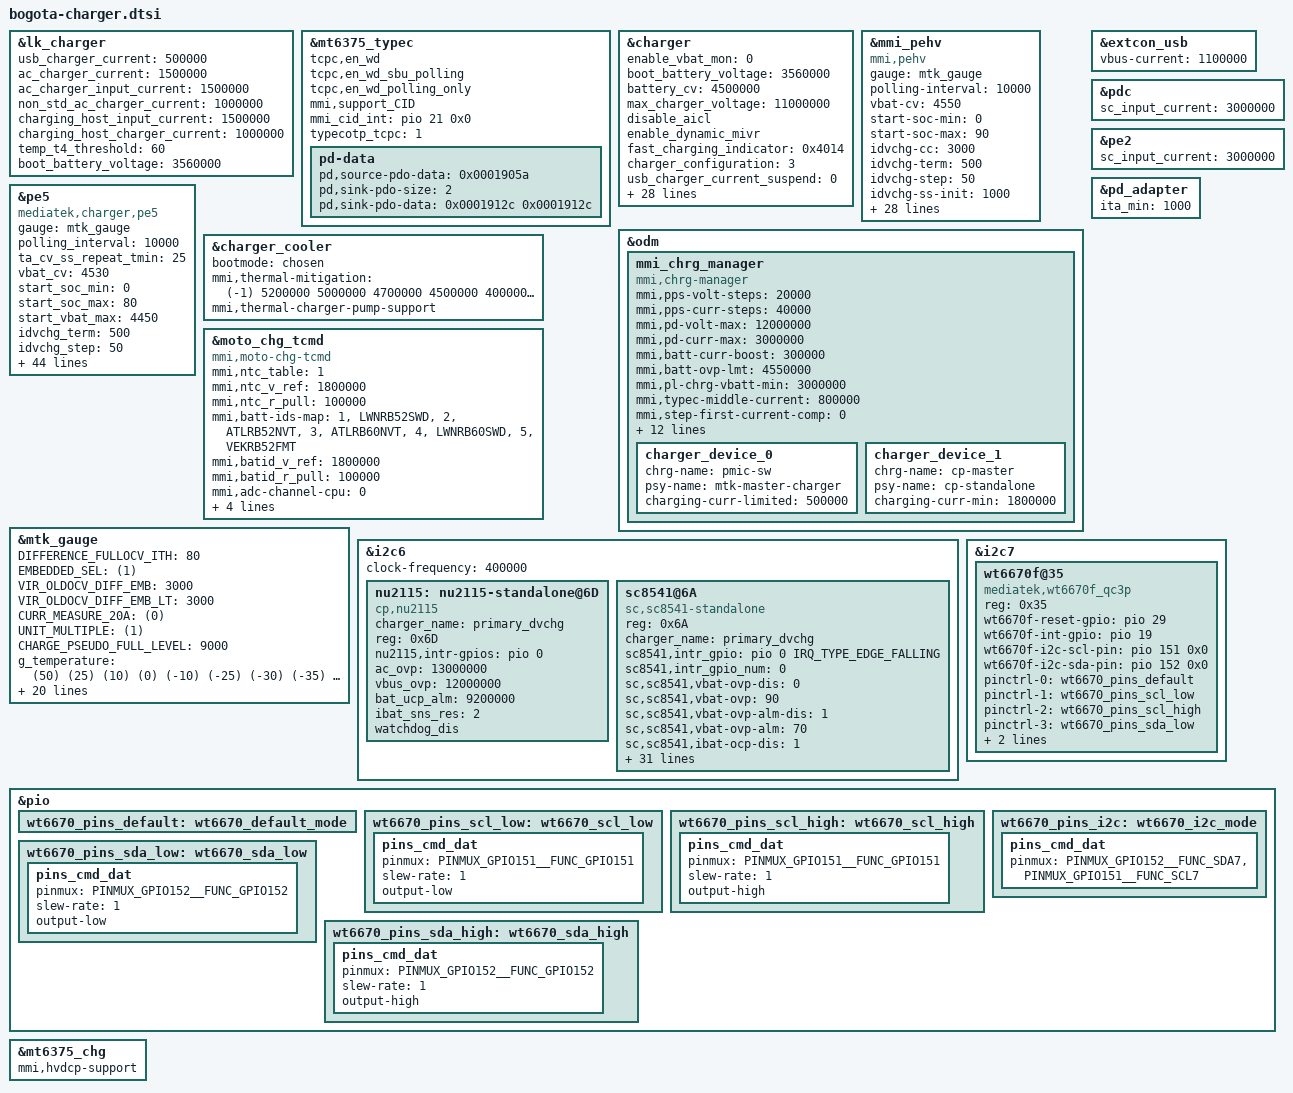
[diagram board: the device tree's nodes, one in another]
/*
 * Copyright (c) 2021 MediaTek Inc.
 *
 * This program is free software; you can redistribute it and/or modify
 * it under the terms of the GNU General Public License version 2 as
 * published by the Free Software Foundation.
 *
 * This program is distributed in the hope that it will be useful,
 * but WITHOUT ANY WARRANTY; without even the implied warranty of
 * MERCHANTABILITY or FITNESS FOR A PARTICULAR PURPOSE.  See the
 * GNU General Public License for more details.
 */

#include <dt-bindings/iio/adc/mediatek,mt6375_adc.h>

&lk_charger {
	/* charging current */
	usb_charger_current = <500000>;
	ac_charger_current = <1500000>;
	ac_charger_input_current = <1500000>;
	non_std_ac_charger_current = <1000000>;
	charging_host_input_current = <1500000>;
	charging_host_charger_current = <1000000>;

	temp_t4_threshold = <60>;

	boot_battery_voltage = <3560000>;
};

&mt6375_typec {
       tcpc,en_wd;
       tcpc,en_wd_sbu_polling;
       tcpc,en_wd_polling_only;
       mmi,support_CID;
       mmi_cid_int = <&pio 21 0x0>;
};

&charger {
        /* sw jeita */
        enable_vbat_mon = <0>;

	/* common */
        boot_battery_voltage = <3560000>;
	battery_cv = <4500000>;
	max_charger_voltage = <11000000>;
//	min_charger_voltage = <4600000>;

        disable_aicl;
        enable_dynamic_mivr;

	/*pehv && pe5 && pdc*/
	fast_charging_indicator = <0x4014>;
	/*swchg + 1CP*/
	charger_configuration= <3>;

	/* charging current */
	usb_charger_current_suspend = <0>;
	usb_charger_current_unconfigured = <70000>;
	usb_charger_current_configured = <500000>;
	usb_charger_current = <500000>;
	ac_charger_current = <3000000>;
	ac_charger_input_current = <2000000>;
	non_std_ac_charger_current = <1000000>;
	charging_host_charger_current = <1500000>;
	apple_1_0a_charger_current = <650000>;
	apple_2_1a_charger_current = <800000>;
	ta_ac_charger_current = <2000000>;
	typec_limit_aicr = <3000000>;
//	typecotp_charger = <1>;

	/*mmi config*/
	mmi,iterm-ma = <255>;
	mmi,mmi-temp-zones = <0 4200 1000 0>,
			<10 4250 2500 1500>,
                        <10 4500 1500 1500>,
			<15 4500 2500 2500>,
			<45 4300 6000 5200>,
			<45 4400 5400 4000>,
			<45 4530 4200 4000>,
			<60 4200 2500 0>;
	mmi,mmi-ffc-zones = <0 4200 255>,
			<10 4500 255>,
			<15 4500 255>,
			<25 4530 692>,
			<35 4530 780>,
			<45 4530 1142>,
			<60 4200 195>;

	mmi,mmi-normal-zones = <0 4200 255>,
			<10 4500 255>,
			<15 4500 255>,
			<25 4500 255>,
			<35 4500 255>,
			<45 4500 510>,
			<60 4200 195>;
	mmi,enable-charging-limit;
	mmi,upper-limit-capacity = <65>;
	mmi,lower-limit-capacity = <60>;
	mmi,min-cp-therm-current-ua = <900000>;
	enable-pdtest-mode = <1>;
};

&mmi_pehv {
	compatible = "mmi,pehv";
	gauge = <&mtk_gauge>;
	polling-interval = <10000>;
	vbat-cv = <4550>;
	start-soc-min = <0>;
	start-soc-max = <90>;
	idvchg-cc = <3000>;
	idvchg-term = <500>;
	idvchg-step = <50>;
	idvchg-ss-init = <1000>;
	idvchg-ss-step = <250>;
	idvchg-ss-step1 = <100>;
	idvchg-ss-step2 = <50>;
	idvchg-ss-step1-vbat = <4000>;
	idvchg-ss-step2-vbat = <4200>;
	ta-blanking = <400>;
	swchg-aicr = <0>;
	swchg-ichg = <1200>;
	swchg-aicr-ss-init = <400>;
	swchg-aicr-ss-step = <200>;
	swchg-off-vbat = <4250>;
	force-ta-cv-vbat = <4250>;
	chg-time-max = <10800>;
	ifod-threshold = <200>;
	rsw-min = <20>;
	ircmp-rbat = <40>;
	ircmp-vclamp = <0>;
	vta-cap-min = <6800>;
	vta-cap-max = <11000>;
	vta-step = <20>;
	ita-cap-min = <1000>;
	vbat-threshold = <4150>;
	min-charger-voltage = <4600000>;
	mmi_therm_cur_thres = <500>;
	mmi_therm_vol_thres = <80>;
	mmi_therm_step = <3>;
	mmi_max_ibat = <6000>;
	ibus-ocp-ratio = <120>;
};

&odm {
	mmi_chrg_manager {
		compatible = "mmi,chrg-manager";
		mmi,pps-volt-steps = <20000>;
		mmi,pps-curr-steps = <40000>;
		mmi,pd-volt-max = <12000000>;
		mmi,pd-curr-max = <3000000>;
		mmi,batt-curr-boost = <300000>;
		mmi,batt-ovp-lmt = <4550000>;
		mmi,pl-chrg-vbatt-min = <3000000>;
		mmi,typec-middle-current = <800000>;
		mmi,step-first-current-comp = <0>;
		mmi,dont-rerun-aicl;
		mmi,chrg-temp-zones-num = <5>;
		mmi,mmi-chrg-temp-zones =
				<0 4200 1000  0 0 0 0>,
				<10 4250 3000 4500 1000 0 0>,
				<15 4500 3000 0 0 0 0>,
				<45 4300 6000 4400 5200 4530 4000>,
				<60 4200 4000 0 0 0 0>;

		mmi,mmi-ffc-zones = <4200 292>,
				<4250 292>,
				<4450 292>,
				<4530 776>,
				<4530 946>,
				<4530 1379>,
				<4200 292>;

		mmi,thermal-min-level = <1500000>;

		charger = <&mt6375_chg>;

		charger_device_0 {
			chrg-name = "pmic-sw";
			psy-name = "mtk-master-charger";
			charging-curr-limited = <500000>;
		};
		charger_device_1 {
			chrg-name = "cp-master";
			psy-name = "cp-standalone";
			charging-curr-min = <1800000>;
		};
	};
};


/*&mt6375_chg {
		io-channels = <&mt6375_adc MT6375_ADC_CHGVIN>,
				      <&mt6375_adc MT6375_ADC_VSYS>,
				      <&mt6375_adc MT6375_ADC_VBAT>,
				      <&mt6375_adc MT6375_ADC_IBUS>,
				      <&mt6375_adc MT6375_ADC_IBAT>,
				      <&mt6375_adc MT6375_ADC_TEMPJC>,
				      <&mt6375_adc MT6375_ADC_USBDP>,
				      <&mt6375_adc MT6375_ADC_USBDM>,
		              <&mt6375_adc MT6375_ADC_VREFTS>,
					  <&mt6375_adc MT6375_ADC_TS>;
		typecotp_chg = <1>;
		pinctrl-names = "mos_on","mos_off";
		pinctrl-0 = <&mos_on>;
		pinctrl-1 = <&mos_off>;

	cv = <4500>;
	ircmp_r = <0>;
	ircmp_v = <0>;
};

&pio {
	mos_on: mos_on {
		pins_cmd_dat {
			pinmux = <PINMUX_GPIO38__FUNC_GPIO38>;
			slew-rate = <1>;
			output-high;
		};
	};
	mos_off: mos_off {
		pins_cmd_dat {
			pinmux = <PINMUX_GPIO38__FUNC_GPIO38>;
			slew-rate = <1>;
			output-low;
		};
	};
};*/

&extcon_usb {
	vbus-current = <1100000>;
};

&pdc {
	sc_input_current = <3000000>;
};

&pe2 {
	sc_input_current = <3000000>;
};

&mt6375_typec {
	typecotp_tcpc = <1>;
	pd-data {
		/* 5V, 900ma */
		pd,source-pdo-data = <0x0001905a>;

		/* 5V, 3A */
		pd,sink-pdo-size = <2>;
		pd,sink-pdo-data = <0x0001912c 0x0001912c> ;
	};
};

&pd_adapter{
	ita_min = <1000>;
};

&pe5 {
		compatible = "mediatek,charger,pe5";
		gauge = <&mtk_gauge>;
		polling_interval = <10000>;
		ta_cv_ss_repeat_tmin = <25>;
		vbat_cv = <4530>;
		start_soc_min = <0>;
		start_soc_max = <80>;
		start_vbat_max = <4450>;
		idvchg_term = <500>;
		idvchg_step = <50>;
		ita_level = <3000 2500 2000 1500>;
		rcable_level = <350 400 500 600>;
		ita_level_dual = <5000 3700 3400 3000>;
		rcable_level_dual = <230 350 450 550>;
		idvchg_ss_init = <1000>;
		idvchg_ss_step = <250>;
		idvchg_ss_step1 = <100>;
		idvchg_ss_step2 = <50>;
		idvchg_ss_step1_vbat = <4000>;
		idvchg_ss_step2_vbat = <4200>;
		ta_blanking = <400>;
		swchg_aicr = <0>;
		swchg_ichg = <1200>;
		swchg_aicr_ss_init = <400>;
		swchg_aicr_ss_step = <200>;
		swchg_off_vbat = <4250>;
		force_ta_cv_vbat = <4250>;
		chg_time_max = <10800>;
		tta_level_def = <0 0 0 0 25 50 60 70 80>;
		tta_curlmt = <0 0 0 0 0 0 0 0 0>;
		tta_recovery_area = <3>;
		tbat_level_def = <0 0 0 5 25 40 43 46 50>;
		tbat_curlmt = <0 0 0 0 0 0 0 0 0>;
		tbat_recovery_area = <3>;
		tdvchg_level_def = <0 0 0 5 25 55 60 65 70>;
		tdvchg_curlmt = <0 0 0 0 0 0 0 0 0>;
		tdvchg_recovery_area = <3>;
		tswchg_level_def = <0 0 0 5 25 65 70 75 80>;
		tswchg_curlmt = <0 0 0 0 0 0 0 0 0>;
		tswchg_recovery_area = <3>;
		ifod_threshold = <200>;
		rsw_min = <20>;
		ircmp_rbat = <40>;
		ircmp_vclamp = <0>;
		vta_cap_min = <6800>;
		vta_cap_max = <11000>;
		ita_cap_min = <1000>;
		support_ta = "pca_ta_pps", "pd_adapter";
		allow_not_check_ta_status;
		vbat_threshold = <4150>;
		mmi_therm_cur_thres = <500>;
		mmi_therm_vol_thres = <80>;
		mmi_therm_step = <3>;
		mmi_max_ibat = <6000>;
};

&charger_cooler {
	bootmode = <&chosen>;
	mmi,thermal-mitigation = <(-1) 5200000 5000000 4700000 4500000 4000000 3400000 3000000 2500000
				2000000 1500000 1000000 800000 500000>;
	mmi,thermal-charger-pump-support;
};

&moto_chg_tcmd {
	compatible = "mmi,moto-chg-tcmd";
	status = "okay";

	mmi,ntc_table = <1>;
	mmi,ntc_v_ref = <1800000>;
	mmi,ntc_r_pull = <100000>;
	mmi,batt-ids-map = "1", "LWNRB52SWD","2", "ATLRB52NVT","3", "ATLRB60NVT","4", "LWNRB60SWD","5", "VEKRB52FMT";
	mmi,batid_v_ref = <1800000>;
	mmi,batid_r_pull = <100000>;

	mmi,adc-channel-cpu = <0>;
	mmi,adc-channel-charger = <2>;
	mmi,adc-channel-pa = <1>;
	mmi,adc-channel-batid = <3>;
	mmi,adc-channel-vbat = <100>;
};

&mtk_gauge {

	DIFFERENCE_FULLOCV_ITH = <80>;  /*gauge cut-off current, should overtop ieoc 50ma*/
	EMBEDDED_SEL = <(1)>;  /*embedded battery,don't remove the battery for user*/
	VIR_OLDOCV_DIFF_EMB = <3000>; /*0.1mv*/
	VIR_OLDOCV_DIFF_EMB_LT = <3000>; /*0.1mv*/
        CURR_MEASURE_20A = <(0)>;
        UNIT_MULTIPLE = <(1)>;
        CHARGE_PSEUDO_FULL_LEVEL = <9000>;

	/* battery prop */
	g_temperature = <(50) (25) (10) (0) (-10) (-25) (-30) (-35) (-40) (-45)>;
	g_FG_PSEUDO100 = <97 97 100 100
		97 97 100 100
		97 97 100 100
		97 97 100 100
		97 97 100 100
		100 100 100 100
		100 100 100 100
		100 100 100 100
		100 100 100 100
		100 100 100 100>;

	g_Q_MAX = <5129 5189 2490 1965
		5239 5238 2468 1984
		5192 5250 2310 1946
		5041 5112 1858 1873
		4894 4977 1843 1851
		2211 1652 1533 1541
		2201 1642 1523 1531
		2191 1632 1513 1521
		2181 1622 1503 1511
		2171 1612 1493 1501>;

	g_Q_MAX_H_CURRENT = <5117 5178 2190 1665
		5222 5224 2168 1684
		5091 5155 2010 1646
		4869 4975 1558 1573
		4484 4423 1543 1551
		2210 1650 1533 1541
		2200 1640 1523 1531
		2190 1630 1513 1521
		2180 1620 1503 1511
		2170 1610 1493 1501>;

	/*vboot voltage for gauge 0%*/
	g_PMIC_MIN_VOL_row = <4>;
	g_PMIC_MIN_VOL_col = <10>;
	g_PMIC_MIN_VOL = <32000  32000  33500  33500
		32000  32000  33000  33000
		33000  33500  33000  33000
		32200  33600  32200  32200
		31360  33500  31360  31360
		31000  31000  31000  31000
		31000  31000  31000  31000
		31000  31000  31000  31000
		31000  31000  31000  31000
		31000  31000  31000  31200>;

	/*Pseudo1 hide percentage*/
	g_QMAX_SYS_VOL_row = <4>;
	g_QMAX_SYS_VOL_col = <10>;
	g_QMAX_SYS_VOL = <32500  32500  34950  34950
		32500  32500  34950  34950
		34250  33500  34250  34250
		34250  33600  34250  34250
		34250  33500  34250  34250
		34250  34250  34250  34250
		32800  32800  32800  32800
		32800  32800  32800  32800
		32800  32800  32800  32800
		32800  32800  32800  32800>;

	SHUTDOWN_1_TIME = <(30)>;
	ACTIVE_TABLE = <(5)>;
	R_FG_VALUE = <(5)>;
	NO_BAT_TEMP_COMPENSATE = <(1)>;
        CAR_TUNE_VALUE = <(100)>;
        df-serialnum = "LWNRB52SWD";
        #include "bat_setting/mt6855_battery_rb52_lwn_5200mah.dtsi"
	#include "bat_setting/mt6855_battery_rb52_atl_5200mah.dtsi"
	#include "bat_setting/mt6855_battery_rb60_swd_6000mah.dtsi"
	#include "bat_setting/mt6855_battery_rb60_atl_6000mah.dtsi"
};

&i2c6 {
	clock-frequency = <400000>;
	nu2115: nu2115-standalone@6D {
		compatible = "cp,nu2115";
		status = "okay";
		charger_name = "primary_dvchg";
		reg = <0x6D>;
		nu2115,intr-gpios = <&pio 0 0x0>;
		ac_ovp = <13000000>;
		vbus_ovp = <12000000>;
		bat_ucp_alm = <9200000>;
		ibat_sns_res = <2>;
		watchdog_dis;
	};

	sc8541@6A {
		compatible = "sc,sc8541-standalone";
		reg = <0x6A>;
		charger_name = "primary_dvchg";
		sc8541,intr_gpio = <&pio 0 IRQ_TYPE_EDGE_FALLING>;
		sc8541,intr_gpio_num = <0>;
		sc,sc8541,vbat-ovp-dis = <0>;
		sc,sc8541,vbat-ovp = <90>; /*3840 + val * 10*/
		sc,sc8541,vbat-ovp-alm-dis = <1>;
		sc,sc8541,vbat-ovp-alm = <70>; /*3840 + val * 10*/
		sc,sc8541,ibat-ocp-dis = <1>;
		sc,sc8541,ibat-ocp  = <82>; /*val * 100*/
		sc,sc8541,ibat-ocp-alm-dis = <1>;
		sc,sc8541,ibat-ocp-alm = <80>; /*val * 100*/
		sc,sc8541,ibus-ucp-dis = <0>;
		sc,sc8541,vbus-in-range-dis = <0>;
		sc,sc8541,vbus-pd-en = <0>;
		sc,sc8541,vbus-ovp = <80>; /*7000 + val * 50*/
		sc,sc8541,vbus-ovp-alm-dis = <1>;
		sc,sc8541,vbus-ovp-alm = <34>; /*7000 + val * 50*/
		sc,sc8541,ibus-ocp-dis = <0>;
		sc,sc8541,ibus-ocp = <13>; /*1000 + val * 250*/
		sc,sc8541,tshut-dis = <1>;
		sc,sc8541,tsbus-flt-dis = <1>;
		sc,sc8541,tsbat-flt-dis = <1>;
		sc,sc8541,tdie-alm = <200>; /*25 + val * 0.5*/
		sc,sc8541,tsbus-flt = <21>;
		sc,sc8541,tsbat-flt = <21>;
		sc,sc8541,vac1-ovp = <2>; /*0:6.5V 1:10.5V 2:12V 3:14V 4:16V 5~7:18V*/
		sc,sc8541,vac2-ovp = <2>; /*0:6.5V 1:10.5V 2:12V 3:14V 4:16V 5~7:18V*/
		sc,sc8541,vac1-pd-en = <0>;
		sc,sc8541,vac2-pd-en = <0>;
		sc,sc8541,fsw-set = <5>; /*0:200KHz 1:300KHz 2:400KHz
					3:500KHz 4:600KHz 5:650KHz 6:700KHz 7:750KHz*/
		sc,sc8541,wd-timeout = <0>; /*0:0.5s 1:1s 2:5s 3:30s*/
		sc,sc8541,wd-timeout-dis = <1>;
		sc,sc8541,ibat-sns-r = <0>; /*0:2mho 1:5mho*/
		sc,sc8541,ss-timeout = <7>; /*0:6.25ms 1:12.5ms 2:25ms 3:50ms
					4:100ms 5:400ms 6:1.5s 7:10s*/
		sc,sc8541,ibus-ucp-fall-dg = <1>;
		sc,sc8541,vout-ovp-dis = <0>;
		sc,sc8541,vout-ovp = <3>; /*4700 + val * 100*/
		sc,sc8541,pmid2out-uvp = <7>; /*50 + val * 25*/
		sc,sc8541,pmid2out-ovp = <7>; /*150 + val * 50*/
	};

};

&i2c7 {
        wt6670f@35 {
                status = "okay";
                compatible = "mediatek,wt6670f_qc3p";
                reg = <0x35>;
                wt6670f-reset-gpio = <&pio 29 0x0>;
                wt6670f-int-gpio = <&pio 19 0x0>;
                wt6670f-i2c-scl-pin = <&pio 151 0x0>;
                wt6670f-i2c-sda-pin = <&pio 152 0x0>;

                pinctrl-names = "default",
                                "wt6670_i2c_scl_low", "wt6670_i2c_scl_high",
                                "wt6670_i2c_sda_low", "wt6670_i2c_sda_high",
                                "wt6670_i2c";
                pinctrl-0 = <&wt6670_pins_default>;
                pinctrl-1 = <&wt6670_pins_scl_low>;
                pinctrl-2 = <&wt6670_pins_scl_high>;
                pinctrl-3 = <&wt6670_pins_sda_low>;
                pinctrl-4 = <&wt6670_pins_sda_high>;
                pinctrl-5 = <&wt6670_pins_i2c>;
        };
};

&pio {
        wt6670_pins_default: wt6670_default_mode {
        };
        wt6670_pins_scl_low: wt6670_scl_low {
                pins_cmd_dat {
                        pinmux = <PINMUX_GPIO151__FUNC_GPIO151>;
                        slew-rate = <1>;
                        output-low;
                };
        };
        wt6670_pins_scl_high: wt6670_scl_high {
                pins_cmd_dat {
                        pinmux = <PINMUX_GPIO151__FUNC_GPIO151>;
                        slew-rate = <1>;
                        output-high;
                };
        };
        wt6670_pins_sda_low: wt6670_sda_low {
                pins_cmd_dat {
                        pinmux = <PINMUX_GPIO152__FUNC_GPIO152>;
                        slew-rate = <1>;
                        output-low;
                };
        };
        wt6670_pins_sda_high: wt6670_sda_high {
                pins_cmd_dat {
                        pinmux = <PINMUX_GPIO152__FUNC_GPIO152>;
                        slew-rate = <1>;
                        output-high;
                };
        };
        wt6670_pins_i2c: wt6670_i2c_mode {
                pins_cmd_dat {
                        pinmux = <PINMUX_GPIO152__FUNC_SDA7>,
                                <PINMUX_GPIO151__FUNC_SCL7>;
                };
        };

};

&mt6375_chg {
	mmi,hvdcp-support;
};
